VERSION ""

NS_ :

BS_:

BU_: FOO BAR

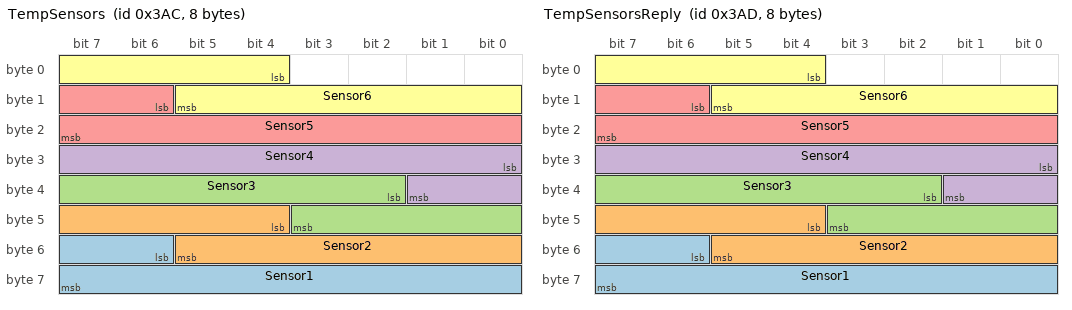
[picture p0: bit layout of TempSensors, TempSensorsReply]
BO_ 940 TempSensors: 8 FOO
    SG_ Sensor1 : 54|10@1- (0.2,0) [0|0] "degC" BAR
    SG_ Sensor2 : 44|10@1- (0.2,0) [0|0] "degC" BAR
    SG_ Sensor3 : 34|10@1- (0.2,0) [0|0] "degC" BAR
    SG_ Sensor4 : 24|10@1- (0.2,0) [0|0] "degC" BAR
    SG_ Sensor5 : 14|10@1- (0.2,0) [0|0] "degC" BAR
    SG_ Sensor6 : 4|10@1- (0.2,0) [0|0] "degC" BAR

BO_ 941 TempSensorsReply: 8 BAR
    SG_ Sensor1 : 54|10@1- (0.2,0) [0|0] "degC" FOO
    SG_ Sensor2 : 44|10@1- (0.2,0) [0|0] "degC" FOO
    SG_ Sensor3 : 34|10@1- (0.2,0) [0|0] "degC" FOO
    SG_ Sensor4 : 24|10@1- (0.2,0) [0|0] "degC" FOO
    SG_ Sensor5 : 14|10@1- (0.2,0) [0|0] "degC" FOO
    SG_ Sensor6 : 4|10@1- (0.2,0) [0|0] "degC" FOO
